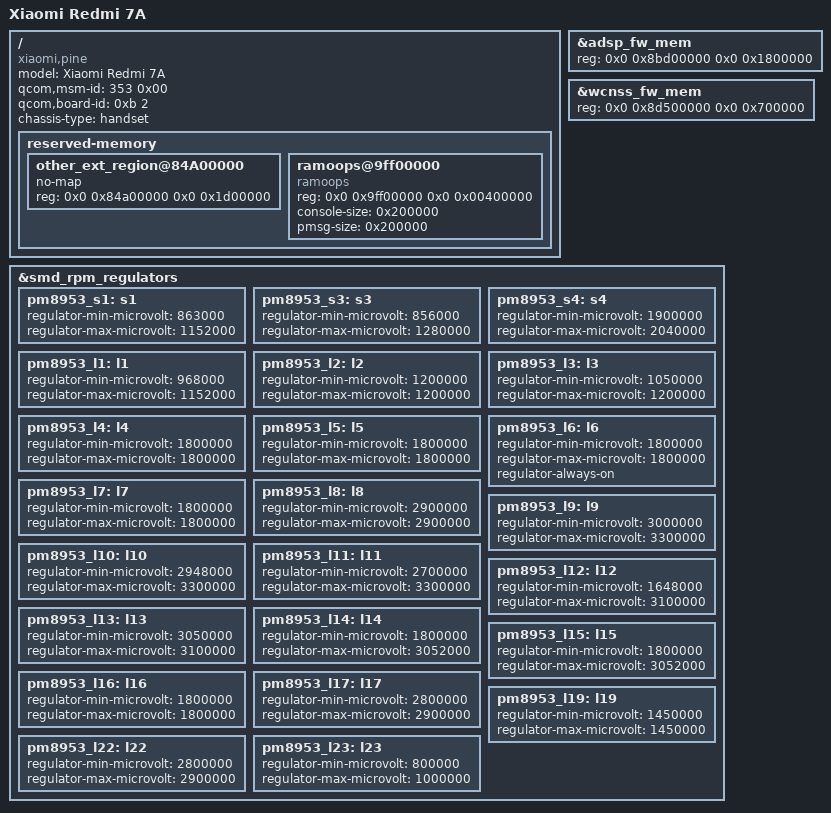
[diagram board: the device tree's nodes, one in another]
/dts-v1/;
#include "sdm439-pm8953.dtsi"

/ {
	model = "Xiaomi Redmi 7A";
	compatible = "xiaomi,pine", "qcom,sdm439";
	qcom,msm-id = <353 0x00>;
	qcom,board-id = <0xb 2>;
	chassis-type = "handset";

	reserved-memory {
		/delete-node/other_ext_region@85b00000;
		other_ext_region@84A00000 {
			no-map;
			reg = <0x0 0x84a00000 0x0 0x1d00000>;
		};

		ramoops@9ff00000 {
			compatible = "ramoops";
			reg = <0x0 0x9ff00000 0x0 0x00400000>;
			console-size = <0x200000>;
			pmsg-size = <0x200000>;
		};
	};
};

&adsp_fw_mem {
	reg = <0x0 0x8bd00000 0x0 0x1800000>;
};

&wcnss_fw_mem {
	reg = <0x0 0x8d500000 0x0 0x700000>;
};

&smd_rpm_regulators {
	pm8953_s1: s1 {
		regulator-min-microvolt = <863000>;
		regulator-max-microvolt = <1152000>;
	};

	pm8953_s3: s3 {
		regulator-min-microvolt = <856000>;
		regulator-max-microvolt = <1280000>;
	};

	pm8953_s4: s4 {
		regulator-min-microvolt = <1900000>;
		regulator-max-microvolt = <2040000>;
	};

	pm8953_l1: l1 {
		regulator-min-microvolt = <968000>;
		regulator-max-microvolt = <1152000>;
	};

	pm8953_l2: l2 {
		regulator-min-microvolt = <1200000>;
		regulator-max-microvolt = <1200000>;
	};

	pm8953_l3: l3 {
		regulator-min-microvolt = <1050000>;
		regulator-max-microvolt = <1200000>;
	};

	pm8953_l4: l4 {
		regulator-min-microvolt = <1800000>;
		regulator-max-microvolt = <1800000>;
	};

	pm8953_l5: l5 {
		regulator-min-microvolt = <1800000>;
		regulator-max-microvolt = <1800000>;
	};

	pm8953_l6: l6 {
		regulator-min-microvolt = <1800000>;
		regulator-max-microvolt = <1800000>;
		regulator-always-on;
	};

	pm8953_l7: l7 {
		regulator-min-microvolt = <1800000>;
		regulator-max-microvolt = <1800000>;
	};

	pm8953_l8: l8 {
		regulator-min-microvolt = <2900000>;
		regulator-max-microvolt = <2900000>;
	};

	pm8953_l9: l9 {
		regulator-min-microvolt = <3000000>;
		regulator-max-microvolt = <3300000>;
	};

	pm8953_l10: l10 {
		regulator-min-microvolt = <2948000>;
		regulator-max-microvolt = <3300000>;
	};

	pm8953_l11: l11 {
		regulator-min-microvolt = <2700000>;
		regulator-max-microvolt = <3300000>;
	};

	pm8953_l12: l12 {
		regulator-min-microvolt = <1648000>;
		regulator-max-microvolt = <3100000>;
	};

	pm8953_l13: l13 {
		regulator-min-microvolt = <3050000>;
		regulator-max-microvolt = <3100000>;
	};

	pm8953_l14: l14 {
		regulator-min-microvolt = <1800000>;
		regulator-max-microvolt = <3052000>;
	};

	pm8953_l15: l15 {
		regulator-min-microvolt = <1800000>;
		regulator-max-microvolt = <3052000>;
	};

	pm8953_l16: l16 {
		regulator-min-microvolt = <1800000>;
		regulator-max-microvolt = <1800000>;
	};

	pm8953_l17: l17 {
		regulator-min-microvolt = <2800000>;
		regulator-max-microvolt = <2900000>;
	};

	pm8953_l19: l19 {
		regulator-min-microvolt = <1450000>;
		regulator-max-microvolt = <1450000>;
	};

	pm8953_l22: l22 {
		regulator-min-microvolt = <2800000>;
		regulator-max-microvolt = <2900000>;
	};

	pm8953_l23: l23 {
		regulator-min-microvolt = <800000>;
		regulator-max-microvolt = <1000000>;
	};
};
